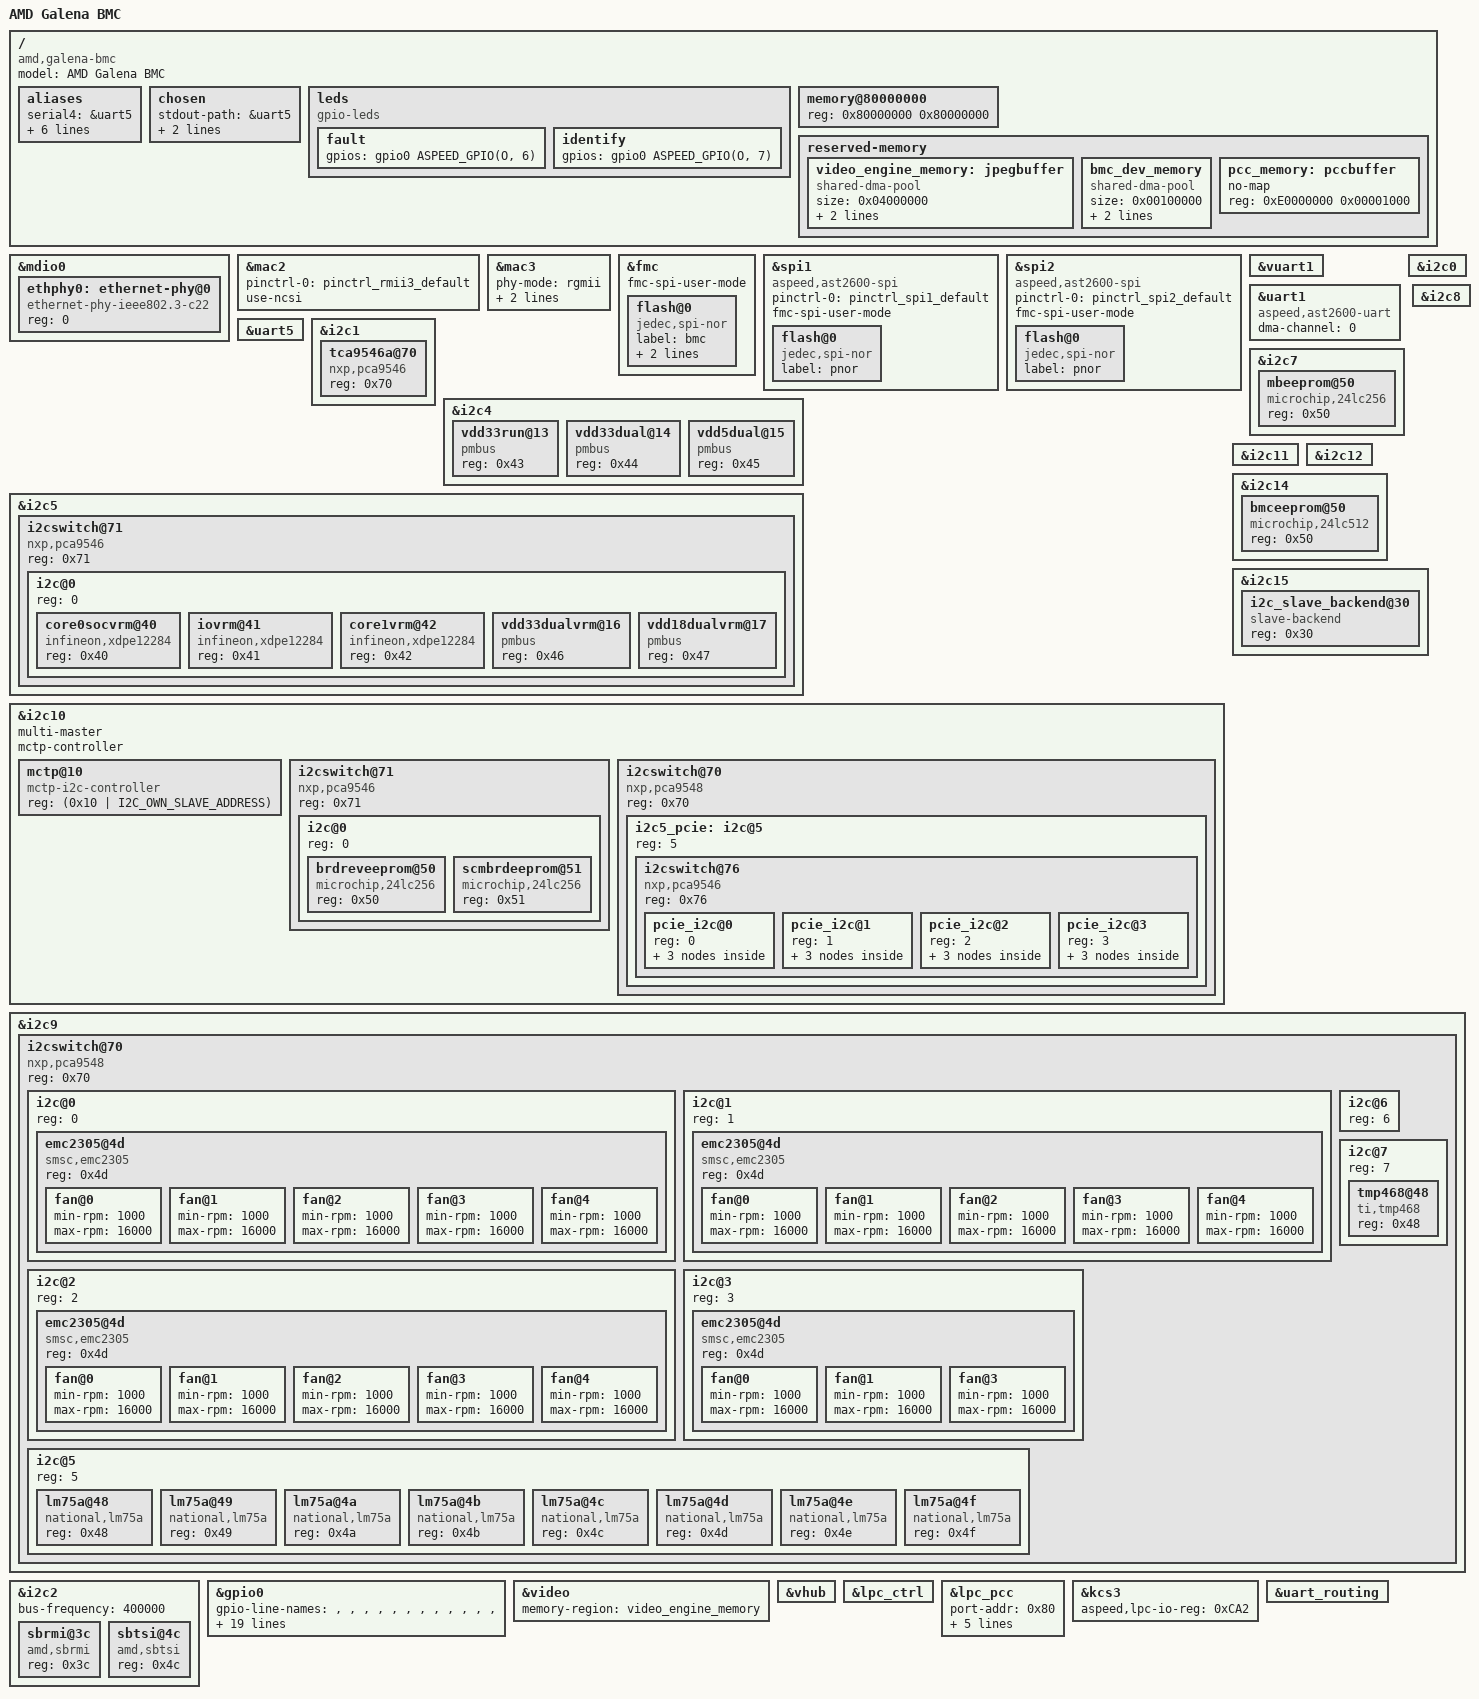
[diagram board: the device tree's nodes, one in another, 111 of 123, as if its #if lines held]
// SPDX-License-Identifier: GPL-2.0
// Copyright (c) 2022 AMD Inc.
// Author: Mohsen Dolaty <mohsen.dolaty@amd.com>
// Author: Supreeth Venkatesh <supreeth.venkatesh@amd.com>

/dts-v1/;
#include "ast2600-amd-bmc-common.dtsi"
#include <dt-bindings/i2c/i2c.h>
#include <dt-bindings/i3c/i3c.h>

/ {
	model = "AMD Galena BMC";
	compatible = "amd,galena-bmc", "aspeed,ast2600";

	aliases {
		serial4 = &uart5;
		ethernet0 = &mac3;
		ethernet1 = &mac2;

		// aliases to the OOB interface for
		// MI350P RM Channels for each PCIe slot.
		i2c180 = &mi350p_slot0_rm_chnl;
		i2c181 = &mi350p_slot1_rm_chnl;
		i2c182 = &mi350p_slot2_rm_chnl;
		i2c183 = &mi350p_slot3_rm_chnl;
	};

	chosen {
		stdout-path = &uart5;
		bootargs = "console=ttyS4,115200 earlycon vmalloc=512MB";
	};

	leds {
		compatible = "gpio-leds";

		fault {
			gpios = <&gpio0 ASPEED_GPIO(O, 6) GPIO_ACTIVE_HIGH>;
		};

		identify {
			gpios = <&gpio0 ASPEED_GPIO(O, 7) GPIO_ACTIVE_HIGH>;
		};
	};

	memory@80000000 {
		device_type = "memory";
		reg = <0x80000000 0x80000000>;
	};

	reserved-memory {
		#address-cells = <1>;
		#size-cells = <1>;
		ranges;

		video_engine_memory: jpegbuffer {
			size = <0x04000000>;	/* 64M */
			alignment = <0x01000000>;
			compatible = "shared-dma-pool";
			reusable;
		};

    bmc_dev_memory: bmc_dev_memory {
           size = <0x00100000>;
           alignment = <0x00100000>;
           compatible = "shared-dma-pool";
           no-map;
    };

		pcc_memory: pccbuffer {
			no-map;
			reg = <0xE0000000 0x00001000>; /* 4K */
		};
	};
};


&mdio0 {
	status = "okay";

	ethphy0: ethernet-phy@0 {
		compatible = "ethernet-phy-ieee802.3-c22";
		reg = <0>;
	};
};

&mac2 {
	status = "okay";
	pinctrl-names = "default";
	pinctrl-0 = <&pinctrl_rmii3_default>;
	clock-names = "MACCLK",	"RCLK";
	use-ncsi;
};

&mac3 {
	status = "okay";
	phy-mode = "rgmii";
	phy-handle = <&ethphy0>;

	pinctrl-names = "default";
	pinctrl-0 = <&pinctrl_rgmii4_default>;
};

&fmc {
	status = "okay";
	fmc-spi-user-mode;
	flash@0 {
		compatible = "jedec,spi-nor";
		status = "okay";
		label = "bmc";
		spi-tx-bus-width = <4>;
		spi-rx-bus-width = <4>;
		#include "openbmc-flash-layout-128.dtsi"
	};
};

&spi1 {
	status = "okay";
	pinctrl-names = "default";
	pinctrl-0 = <&pinctrl_spi1_default>;
	fmc-spi-user-mode;
	compatible = "aspeed,ast2600-spi";

	flash@0 {
		compatible = "jedec,spi-nor";
		label = "pnor";
		status = "okay";
	};

};

&spi2 {
	status = "okay";
	pinctrl-names = "default";
	pinctrl-0 = <&pinctrl_spi2_default>;
	fmc-spi-user-mode;
	compatible = "aspeed,ast2600-spi";

	flash@0 {
		compatible = "jedec,spi-nor";
		label = "pnor";
		status = "okay";
	};

};

// eSPI Virtual UART - 0x3F8
&vuart1 {
	status = "okay";
};
&uart1 {
	//Host console
	compatible = "aspeed,ast2600-uart";
	/delete-property/ reg-shift;
	/delete-property/ reg-io-width;
	//dma-mode;
	dma-channel = <0>;
	status = "okay";
};

//BMC Console
&uart5 {
	status = "okay";
};

// I2C configs
&i2c0 {
	//Net name i2c9 - MB FPGA slave
	status = "okay";
};

&i2c1 {
	//Net name i2c10 - galena side i2c12
	// Connected to TCA9546A and to LCD HDR
	status = "okay";
#ifdef OPENBMC_LCD_DRIVER
	tca9546a@70 {
		compatible = "nxp,pca9546";
		reg = <0x70>;
		//<TBD> Define LCD details here
	};
#endif //OPENBMC_LCD_DRIVER
};

&i2c4 {
	// Net name i2c1
	status = "okay";
	vdd33run@13 {
		//VDD_33_RUN VRM
		compatible = "pmbus";
		reg = <0x43>;
	};
	vdd33dual@14 {
		//VDD_33_DUAL VRM
		compatible = "pmbus";
		reg = <0x44>;
	};
	vdd5dual@15 {
		//VDD_5_DUAL VRM
		compatible = "pmbus";
		reg = <0x45>;
	};
};

// BMC galena VRs
&i2c5 {
	// Net name i2c2 (SCM_I2C2)
	status = "okay";

	i2cswitch@71 {
		compatible = "nxp,pca9546";
		reg = <0x71>;
		#address-cells = <1>;
		#size-cells = <0>;

		i2c@0 {
			#address-cells = <1>;
			#size-cells = <0>;
			reg = <0>;
			core0socvrm@40 {
				//VDD core0/soc VRM
				compatible = "infineon,xdpe12284";
				reg = <0x40>;
			};
			iovrm@41 {
				//VDD io VRM
				compatible = "infineon,xdpe12284";
				reg = <0x41>;
			};
			core1vrm@42 {
				//VDD core1 VRM
				compatible = "infineon,xdpe12284";
				reg = <0x42>;
			};
			vdd33dualvrm@16 {
				//VDD 33 DUAL VRM
				compatible = "pmbus";
				reg = <0x46>;
			};
			vdd18dualvrm@17 {
				//VDD 18 DUAL VRM
				compatible = "pmbus";
				reg = <0x47>;
			};
		};
	};
};

&i2c7 {
	// Net name i2c4
	status = "okay";

	mbeeprom@50 {
	compatible = "microchip,24lc256","atmel,24c256";
	reg = <0x50>;
	};
};

&i2c8 {
	// Net name i2c5 - PSU
	status = "okay";
};

&i2c10 {
	// Net name i2c7
	status = "okay";
	multi-master;
	mctp-controller;
	mctp@10 {
		compatible = "mctp-i2c-controller";
		reg = <(0x10 | I2C_OWN_SLAVE_ADDRESS)>;
	};

#ifdef EEPROM_PROG_ENABLE

	i2cswitch@71 {
		compatible = "nxp,pca9546";
		reg = <0x71>;
		#address-cells = <1>;
		#size-cells = <0>;

		i2c@0 {
			#address-cells = <1>;
			#size-cells = <0>;
			reg = <0>;

			brdreveeprom@50 {
				//Galena BRD ID
				compatible = "microchip,24lc256","atmel,24c256";
				reg = <0x50>;
			};

			scmbrdeeprom@51 {
				//SCM BRD ID
				compatible = "microchip,24lc256","atmel,24c256";
				reg = <0x51>;
			};
		};

	};
#endif

	// galena mapping for i2c to pcie-slot
	// i2c0x70 -- port 5 --- i2c0x73h(amber)/0x76h(caramel) --- port 0 to 3
	i2cswitch@70 {
		compatible = "nxp,pca9548";
		reg = <0x70>;
		#address-cells = <1>;
		#size-cells = <0>;

		i2c5_pcie: i2c@5 {
			reg = <5>;
			#address-cells = <1>;
			#size-cells = <0>;

			i2cswitch@76 {
			compatible = "nxp,pca9546";
				reg = <0x76>;
				#address-cells = <1>;
				#size-cells = <0>;

				// PCIe slot0 on the Galena
				pcie_i2c@0 {
					reg = <0>;
					#address-cells = <1>;
					#size-cells = <0>;

					// following switch is on the MI350P card not on the Galena
					i2cswitch@77 {
						compatible = "nxp,pca9546";
						reg = <0x77>;
						#address-cells = <1>;
						#size-cells = <0>;
						mi350p_slot0_rm_chnl: mi350p_rm@0 {
							reg = <0>; #address-cells = <1>; #size-cells = <0>;
							mctp-controller;
							fru_eprom@56 {
								compatible = "microchip,24lc512","atmel,24c512";
								reg = <0x56>;
							};
						};
					};
				};

				// PCIe slot0 on the Galena
				pcie_i2c@1 {
					reg = <1>;
					#address-cells = <1>;
					#size-cells = <0>;

					// following switch is on the MI350P card not on the Galena
					i2cswitch@77 {
						compatible = "nxp,pca9546";
						reg = <0x77>;
						#address-cells = <1>;
						#size-cells = <0>;
						mi350p_slot1_rm_chnl: mi350p_rm@0 {
							reg = <0>; #address-cells = <1>; #size-cells = <0>;
							mctp-controller;
                                                        fru_eprom@56 {
                                                                compatible = "microchip,24lc512","atmel,24c512";
                                                                reg = <0x56>;
                                                        };							
						};
					};
				};

				// PCIe slot2 on the Galena
				pcie_i2c@2 {
					reg = <2>;
					#address-cells = <1>;
					#size-cells = <0>;
					// following switch is on the MI350P card not on the Galena
					i2cswitch@77 {
						compatible = "nxp,pca9546";
						reg = <0x77>;
						#address-cells = <1>;
						#size-cells = <0>;
						mi350p_slot2_rm_chnl: mi350p_rm@0 {
							reg = <0>; #address-cells = <1>; #size-cells = <0>;
							mctp-controller;
                                                        fru_eprom@56 {
                                                                compatible = "microchip,24lc512","atmel,24c512";
                                                                reg = <0x56>;
                                                        };							
						};
					};
				};

				// PCIe slot3 on the Galena
				pcie_i2c@3 {
					reg = <3>;
					#address-cells = <1>;
					#size-cells = <0>;
					// following switch is on the MI350P card not on the Galena
					i2cswitch@77 {
						compatible = "nxp,pca9546";
						reg = <0x77>;
						#address-cells = <1>;
						#size-cells = <0>;
						mi350p_slot3_rm_chnl: mi350p_rm@0 {
							reg = <0>; #address-cells = <1>; #size-cells = <0>;
							mctp-controller;
                                                        fru_eprom@56 {
                                                                compatible = "microchip,24lc512","atmel,24c512";
                                                                reg = <0x56>;
                                                        };							
						};
					};
				};
			}; // switch76
		}; // i2c5_pcie
	}; // switch 70
};

&i2c11 {
	// Net name i2c8 - MB LOM
	status = "okay";
};

&i2c12 {
	// LOCAL MGMT - FPGA slave
	status = "okay";
};

&i2c14 {
	// LOCAL MGMT - EEPROM, RTC
	status = "okay";
	bmceeprom@50 {
	compatible = "microchip,24lc512","atmel,24c512";
	reg = <0x50>;
	};
};

&i2c15 {
	// RoT
	status = "okay";
	i2c_slave_backend@30 {
		compatible = "slave-backend";
		reg = <0x30>;
	};
};

&i2c9 {
	// Net name i2c6
	status = "okay";

	i2cswitch@70 {
		compatible = "nxp,pca9548";
		reg = <0x70>;
		#address-cells = <1>;
		#size-cells = <0>;

		//  port 0 to 3 connected to 4 fan controllers which controls 5 fans each
		i2c@0 {
			reg = <0>;
			#address-cells = <1>;
			#size-cells = <0>;

			emc2305@4d {
				compatible = "smsc,emc2305";
				reg = <0x4d>;
				#cooling-cells = <0x02>;

				fan@0 {
					min-rpm = /bits/ 16 <1000>;
					max-rpm = /bits/ 16 <16000>;
				};
				fan@1 {
					min-rpm = /bits/ 16 <1000>;
					max-rpm = /bits/ 16 <16000>;
				};

				fan@2 {
					min-rpm = /bits/ 16 <1000>;
					max-rpm = /bits/ 16 <16000>;
				};

				fan@3 {
					min-rpm = /bits/ 16 <1000>;
					max-rpm = /bits/ 16 <16000>;
				};

				fan@4 {
					min-rpm = /bits/ 16 <1000>;
					max-rpm = /bits/ 16 <16000>;
				};
			};
		};

		i2c@1 {
			reg = <1>;
			#address-cells = <1>;
			#size-cells = <0>;

			emc2305@4d {
				compatible = "smsc,emc2305";
				reg = <0x4d>;
				#cooling-cells = <0x02>;

				fan@0 {
					min-rpm = /bits/ 16 <1000>;
					max-rpm = /bits/ 16 <16000>;
				};
				fan@1 {
					min-rpm = /bits/ 16 <1000>;
					max-rpm = /bits/ 16 <16000>;
				};

				fan@2 {
					min-rpm = /bits/ 16 <1000>;
					max-rpm = /bits/ 16 <16000>;
				};

				fan@3 {
					min-rpm = /bits/ 16 <1000>;
					max-rpm = /bits/ 16 <16000>;
				};

				fan@4 {
					min-rpm = /bits/ 16 <1000>;
					max-rpm = /bits/ 16 <16000>;
				};
			};
		};

		i2c@2 {
			reg = <2>;
			#address-cells = <1>;
			#size-cells = <0>;

			emc2305@4d {
				compatible = "smsc,emc2305";
				reg = <0x4d>;
				#cooling-cells = <0x02>;

				fan@0 {
					min-rpm = /bits/ 16 <1000>;
					max-rpm = /bits/ 16 <16000>;
				};
				fan@1 {
					min-rpm = /bits/ 16 <1000>;
					max-rpm = /bits/ 16 <16000>;
				};

				fan@2 {
					min-rpm = /bits/ 16 <1000>;
					max-rpm = /bits/ 16 <16000>;
				};

				fan@3 {
					min-rpm = /bits/ 16 <1000>;
					max-rpm = /bits/ 16 <16000>;
				};

				fan@4 {
					min-rpm = /bits/ 16 <1000>;
					max-rpm = /bits/ 16 <16000>;
				};
			};
		};

		i2c@3 {
			reg = <3>;
			#address-cells = <1>;
			#size-cells = <0>;

			emc2305@4d {
				compatible = "smsc,emc2305";
				reg = <0x4d>;
				#cooling-cells = <0x02>;

				fan@0 {
					min-rpm = /bits/ 16 <1000>;
					max-rpm = /bits/ 16 <16000>;
				};
				fan@1 {
					min-rpm = /bits/ 16 <1000>;
					max-rpm = /bits/ 16 <16000>;
				};

				fan@3 {
					min-rpm = /bits/ 16 <1000>;
					max-rpm = /bits/ 16 <16000>;
				};
			};
		};

		i2c@5 {
			#address-cells = <1>;
			#size-cells = <0>;
			reg = <5>;

			lm75a@48 {
				compatible = "national,lm75a";
				reg = <0x48>;
			};

			lm75a@49 {
				compatible = "national,lm75a";
				reg = <0x49>;
			};

			lm75a@4a {
				compatible = "national,lm75a";
				reg = <0x4a>;
			};

			lm75a@4b {
				compatible = "national,lm75a";
				reg = <0x4b>;
			};

			lm75a@4c {
				compatible = "national,lm75a";
				reg = <0x4c>;
			};

			lm75a@4d {
				compatible = "national,lm75a";
				reg = <0x4d>;
			};

			lm75a@4e {
				compatible = "national,lm75a";
				reg = <0x4e>;
			};

			lm75a@4f {
				compatible = "national,lm75a";
				reg = <0x4f>;
			};
		};

		i2c@6 {
			#address-cells = <1>;
			#size-cells = <0>;
			reg = <6>;
		};

		i2c@7 {
			#address-cells = <1>;
			#size-cells = <0>;
			reg = <7>;

			tmp468@48 {
				compatible = "ti,tmp468";
				reg = <0x48>;
			};
		};
	};
};



&i2c2 {
	// P0 APML - i2c10
	status = "okay";
	bus-frequency = <400000>;

	sbrmi@3c {
	compatible = "amd,sbrmi";
		reg = <0x3c>;
	};

	sbtsi@4c {
		compatible = "amd,sbtsi";
		reg = <0x4c>;
	};
};

&gpio0 {
	gpio-line-names =
	/*A0-A7*/	"","","","","","","","",
	/*B0-B7*/	"","","","","MON_POST_COMPLETE","P0_PRESENT_L","","",
	/*C0-C7*/	"","","","","","","","",
	/*D0-D7*/	"","","","","","","","",
	/*E0-E7*/	"","","","","","","","",
	/*F0-F7*/	"","","","","","","","",
	/*G0-G7*/	"","","","","","","","MON_RSMRST_L",
	/*H0-H7*/	"","ASSERT_WARM_RST_BTN_L","ASSERT_SOC_RST_BTN_L","","","","","",
	/*I0-I7*/	"","","","","","","","P0_I3C_APML_ALERT_L",
	/*J0-J7*/	"","","","","","","","",
	/*K0-K7*/	"","","","","","","","",
	/*L0-L7*/	"","","","","","","","",
	/*M0-M7*/	"","","","","","","","",
	/*N0-N7*/	"","","P0_THERMTRIP_L","","","","PSP_SOFT_FUSE_NOTIFY","ASSERT_BMC_READY",
	/*O0-O7*/	"","","HDT_SEL","HDT_XTRIG5","HDT_XTRIG6","JTAG_TRST_N","","",
	/*P0-P7*/	"MON_RST_BTN_L","ASSERT_RST_BTN_L","MON_PWR_BTN_L","ASSERT_PWR_BTN_L","","ASSERT_NMI_BTN_L","MON_PWR_GOOD","",
	/*Q0-Q7*/	"","","HDT_DBREQ_L","","BIOS_SPD_MUX_CTRL_RELEASED_L","","","",
	/*R0-R7*/	"","","","","","","","",
	/*S0-S7*/	"","","","","","","P0_DIMM_AF_ERROR","P0_DIMM_GL_ERROR",
	/*T0-T7*/	"","","","","","","","",
	/*U0-U7*/	"","","","","","","","",
	/*V0-V7*/	"","","","RSMRST","","","","",
	/*W0-W7*/	"","","","","","","","",
	/*X0-X7*/	"","","","","","","","",
	/*Y0-Y7*/	"","","","","","","","",
	/*Z0-Z7*/	"","","","","","","","";
};


&video {
	status = "okay";
	memory-region = <&video_engine_memory>;
};

&vhub {
	status = "okay";
};

&lpc_ctrl {
	status = "okay";
};

&lpc_pcc {
	port-addr = <0x80>;
	dma-mode;
	memory-region = <&pcc_memory>;
	rec-mode = <0x1>;
	port-addr-hbits-select = <0x1>;
	port-addr-xbits = <0x3>;

	status = "okay";
};

&kcs3 {
	status = "okay";
	aspeed,lpc-io-reg = <0xCA2>;
};

&uart_routing {
	status = "okay";
};
